AUTOSAR XML (schema 4-2-2)
package /ParkBrake_FlatView/SwComponentTypes
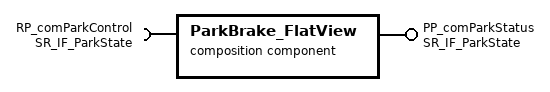
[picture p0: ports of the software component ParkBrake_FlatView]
  composition sw component type ParkBrake_FlatView
    provide port PP_comParkStatus: provided-interface=SR_IF_ParkState
    require port RP_comParkControl: required-interface=SR_IF_ParkState
    8 x component:
      CPT_ComSWC: type=ComSWC
      CPT_MemSWC: type=MemSWC
      CPT_ParkSWC: type=ParkSWC
      CPT_SystemSWC: type=SystemSWC
      CPT_ComM: type=ComM
      CPT_NvM: type=NvM
      CPT_EcuM: type=EcuM
      CPT_BswM: type=BswM
    connect CPT_ComSWC.PP_ParkControl -> CPT_ParkSWC.RP_ParkControl
    connect CPT_ParkSWC.PP_ParkStatus -> CPT_ComSWC.RP_ParkStatus
    connect CPT_ParkSWC.PP_ParkStatus -> CPT_MemSWC.RP_ParkStatus
    delegate CPT_ComSWC.PP_comParkStatus <-> outer port PP_comParkStatus
    delegate CPT_ComSWC.RP_comParkControl <-> outer port RP_comParkControl
    connect CPT_NvM.NvM_NativeBlock_2 -> CPT_MemSWC.RP_NvM_ParkStatus
    connect CPT_SystemSWC.PP_ShutdownRequest -> CPT_BswM.RP_BswM_MRP_SwcModeRequest
